# PIC32CZ2051CA70144 device description
Architecture: CORTEX-M7; Family: PIC32C; Series: PIC32CZCA70
Registers are 32-bit, read-write, no defined reset value unless marked. A register's access mark holds for its fields unless they carry their own. Offsets are from the block's base; [hi:lo] are bit positions; {n}, {i} and the like mark numbered series; 'fields as' and 'values as' point back to an identical list.

## DACC — Digital-to-Analog Converter Controller
Instances: DACC 0x40040000
0x00 DACC_CR wo — Control Register
  [0] SWRST — Software Reset
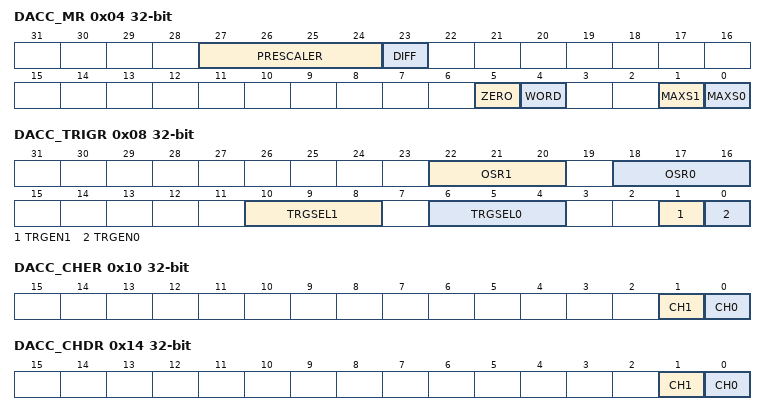
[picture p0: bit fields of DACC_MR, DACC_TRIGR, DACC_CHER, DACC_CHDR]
0x04 DACC_MR — Mode Register
  [27:24] PRESCALER — Peripheral Clock to DAC Clock Ratio
  [23] DIFF — Differential Mode
    0=DISABLED (DAC0 and DAC1 are single-ended outputs.); 1=ENABLED (DACP and DACN are differential outputs. The differential level is configured by the channel 0 value.)
  [5] ZERO — Must always be written to 0.
  [4] WORD — Word Transfer Mode
    0=DISABLED (One data to convert is written to the FIFO per access to DACC.); 1=ENABLED (Two data to convert are written to the FIFO per access to DACC (reduces the number of requests to DMA and the number of system bus accesses).)
  [1] MAXS1 — Max Speed Mode for Channel 1
    0=TRIG_EVENT (External trigger mode or Free-running mode enabled. (See TRGENx.DACC_TRIGR.)); 1=MAXIMUM (Max speed mode enabled.)
  [0] MAXS0 — Max Speed Mode for Channel 0
    values as MAXS1
0x08 DACC_TRIGR — Trigger Register
  [22:20] OSR1 — Over Sampling Ratio of Channel 1
    0=OSR_1; 1=OSR_2; 2=OSR_4; 3=OSR_8; 4=OSR_16; 5=OSR_32
  [18:16] OSR0 — Over Sampling Ratio of Channel 0
    0=OSR_1; 1=OSR_2; 2=OSR_4; 3=OSR_8; 4=OSR_16; 5=OSR_32
  [10:8] TRGSEL1 — Trigger Selection of Channel 1
    0=TRGSEL0 (DAC External Trigger Input (DATRG)); 1=TRGSEL1 (TC0 Channel 0 Output (TIOA0)); 2=TRGSEL2 (TC0 Channel 1 Output (TIOA1)); 3=TRGSEL3 (TC0 Channel 2 Output (TIOA2)); 4=TRGSEL4 (PWM0 Event Line 0); 5=TRGSEL5 (PWM0 Event Line 1); 6=TRGSEL6 (PWM1 Event Line 0); 7=TRGSEL7 (PWM1 Event Line 1)
  [6:4] TRGSEL0 — Trigger Selection of Channel 0
    values as TRGSEL1
  [1] TRGEN1 — Trigger Enable of Channel 1
    0=DIS (External trigger mode disabled. DACC is in Free-running mode or Max speed mode.); 1=EN (External trigger mode enabled.)
  [0] TRGEN0 — Trigger Enable of Channel 0
    values as TRGEN1
0x10 DACC_CHER wo (atomic set of DACC_CHSR) — Channel Enable Register
  [1] CH1 — Channel 1 Enable
  [0] CH0 — Channel 0 Enable
0x14 DACC_CHDR wo (atomic clear of DACC_CHSR) — Channel Disable Register
  [1] CH1 — Channel 1 Disable
  [0] CH0 — Channel 0 Disable
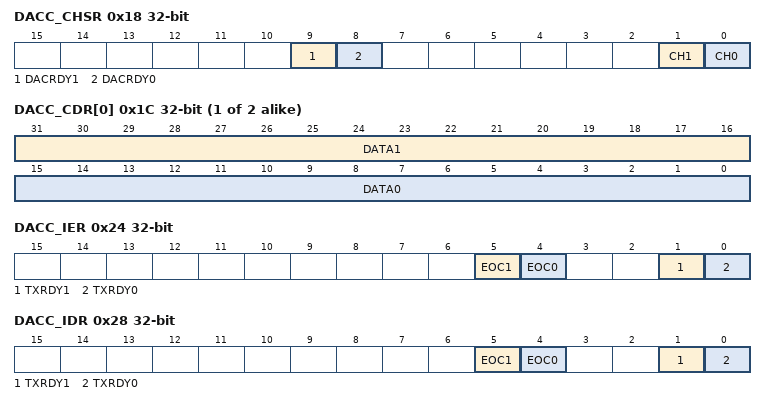
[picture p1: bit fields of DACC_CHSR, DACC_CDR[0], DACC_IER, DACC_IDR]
0x18 DACC_CHSR ro — Channel Status Register
  [9] DACRDY1 — DAC Ready Flag
  [8] DACRDY0 — DAC Ready Flag
  [1] CH1 — Channel 1 Status
  [0] CH0 — Channel 0 Status
{0x1C+4i} DACC_CDR[{i}] (i=0..1) wo — Conversion Data Register 0
  [31:16] DATA1 — Data to Convert for channel 1
  [15:0] DATA0 — Data to Convert for channel 0
0x24 DACC_IER wo (atomic set of DACC_IMR) — Interrupt Enable Register
  [5] EOC1 — End of Conversion Interrupt Enable of channel 1
  [4] EOC0 — End of Conversion Interrupt Enable of channel 0
  [1] TXRDY1 — Transmit Ready Interrupt Enable of channel 1
  [0] TXRDY0 — Transmit Ready Interrupt Enable of channel 0
0x28 DACC_IDR wo (atomic clear of DACC_IMR) — Interrupt Disable Register
  [5] EOC1 — End of Conversion Interrupt Disable of channel 1
  [4] EOC0 — End of Conversion Interrupt Disable of channel 0
  [1] TXRDY1 — Transmit Ready Interrupt Disable of channel 1
  [0] TXRDY0 — Transmit Ready Interrupt Disable of channel 0
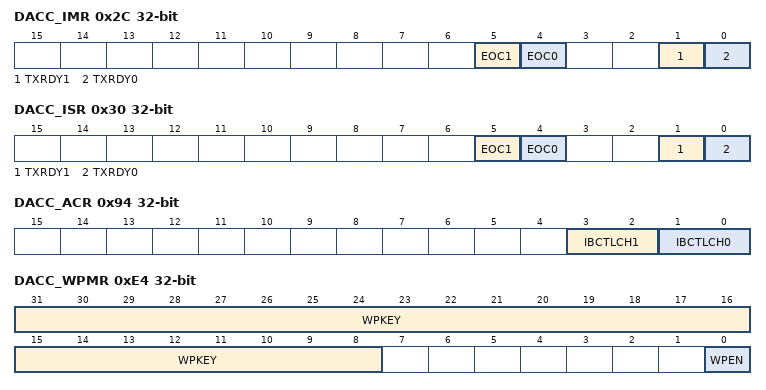
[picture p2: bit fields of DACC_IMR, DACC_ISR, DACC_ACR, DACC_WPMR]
0x2C DACC_IMR ro (atomic read) — Interrupt Mask Register
  [5] EOC1 — End of Conversion Interrupt Mask of channel 1
  [4] EOC0 — End of Conversion Interrupt Mask of channel 0
  [1] TXRDY1 — Transmit Ready Interrupt Mask of channel 1
  [0] TXRDY0 — Transmit Ready Interrupt Mask of channel 0
0x30 DACC_ISR ro (atomic clear) — Interrupt Status Register
  [5] EOC1 — End of Conversion Interrupt Flag of channel 1
  [4] EOC0 — End of Conversion Interrupt Flag of channel 0
  [1] TXRDY1 — Transmit Ready Interrupt Flag of channel 1
  [0] TXRDY0 — Transmit Ready Interrupt Flag of channel 0
0x94 DACC_ACR — Analog Current Register
  [3:2] IBCTLCH1 — Analog Output Current Control
  [1:0] IBCTLCH0 — Analog Output Current Control
0xE4 DACC_WPMR — Write Protection Mode Register
  [31:8] WPKEY — Write Protect Key
    0x444143=PASSWD (Writing any other value in this field aborts the write operation of bit WPEN.Always reads as 0.)
  [0] WPEN — Write Protection Enable
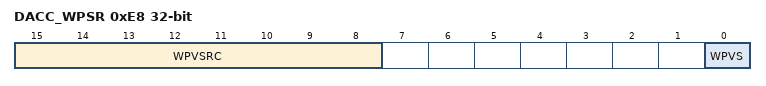
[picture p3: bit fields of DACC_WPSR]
0xE8 DACC_WPSR ro — Write Protection Status Register
  [15:8] WPVSRC — Write Protection Violation Source
  [0] WPVS — Write Protection Violation Status
